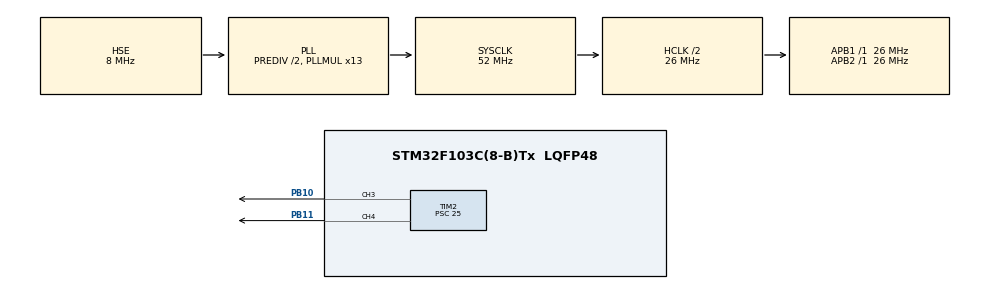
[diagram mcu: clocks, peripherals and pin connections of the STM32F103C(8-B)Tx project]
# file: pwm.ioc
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Mcu.Family=STM32F1
Mcu.Name=STM32F103C(8-B)Tx
Mcu.Package=LQFP48
NVIC.PriorityGroup=NVIC_PRIORITYGROUP_4
PA13.Mode=Serial_Wire
PA13.Signal=SYS_JTMS-SWDIO
PA14.Mode=Serial_Wire
PA14.Signal=SYS_JTCK-SWCLK
PB10.Signal=S_TIM2_CH3
PB11.Signal=S_TIM2_CH4
PD0-OSC_IN.Mode=HSE-External-Oscillator
PD0-OSC_IN.Signal=RCC_OSC_IN
PD1-OSC_OUT.Mode=HSE-External-Oscillator
PD1-OSC_OUT.Signal=RCC_OSC_OUT
ProjectManager.HeapSize=0x200
ProjectManager.StackSize=0x400
ProjectManager.TargetToolchain=STM32CubeIDE
RCC.AHBCLKDivider=RCC_SYSCLK_DIV2
RCC.AHBFreq_Value=26000000
RCC.APB1Freq_Value=26000000
RCC.APB1TimFreq_Value=26000000
RCC.APB2Freq_Value=26000000
RCC.APB2TimFreq_Value=26000000
RCC.HCLKFreq_Value=26000000
RCC.HSEDivPLL=RCC_HSE_PREDIV_DIV2
RCC.PLLMUL=RCC_PLL_MUL13
RCC.PLLSourceVirtual=RCC_PLLSOURCE_HSE
RCC.SYSCLKFreq_VALUE=52000000
RCC.SYSCLKSource=RCC_SYSCLKSOURCE_PLLCLK
RCC.USBFreq_Value=52000000
SH.S_TIM2_CH3.0=TIM2_CH3,PWM Generation3 CH3
SH.S_TIM2_CH4.0=TIM2_CH4,PWM Generation4 CH4
TIM2.Channel-PWM\ Generation3\ CH3=TIM_CHANNEL_3
TIM2.Channel-PWM\ Generation4\ CH4=TIM_CHANNEL_4
TIM2.Period=99
TIM2.Prescaler=25
VP_TIM2_VS_ClockSourceINT.Mode=Internal
board=custom

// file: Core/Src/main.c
/* USER CODE BEGIN Header */
/**
  ******************************************************************************
  * @file           : main.c
  * @brief          : Main program body
  ******************************************************************************
  * @attention
  *
  * Copyright (c) 2024 STMicroelectronics.
  * All rights reserved.
  *
  * This software is licensed under terms that can be found in the LICENSE file
  * in the root directory of this software component.
  * If no LICENSE file comes with this software, it is provided AS-IS.
  *
  ******************************************************************************
  */
/* USER CODE END Header */
#include "main.h"

TIM_HandleTypeDef htim2;

void SystemClock_Config(void);
static void MX_GPIO_Init(void);
static void MX_TIM2_Init(void);

/* USER CODE BEGIN 0 */
void pwm_set_red(uint8_t dc) {
	uint32_t arr;
	uint32_t ccr;

	arr  =__HAL_TIM_GET_AUTORELOAD(&htim2);
	arr += 1;

	ccr = (dc * arr) / 100;
	__HAL_TIM_SET_COMPARE(&htim2, TIM_CHANNEL_3, ccr);
}

void pwm_set_blue(uint8_t dc) {
	uint32_t arr;
	uint32_t ccr;

	arr  =__HAL_TIM_GET_AUTORELOAD(&htim2);
	arr += 1;

	ccr = dc * arr / 100;
	__HAL_TIM_SET_COMPARE(&htim2, TIM_CHANNEL_4, ccr);
}
/* USER CODE END 0 */

int main(void)
{

  /* USER CODE BEGIN 1 */
	uint32_t cntB, step;
  /* USER CODE END 1 */

  /* MCU Configuration--------------------------------------------------------*/

  /* Reset of all peripherals, Initializes the Flash interface and the Systick. */
  HAL_Init();

  /* Configure the system clock */
  SystemClock_Config();

  /* Initialize all configured peripherals */
  MX_GPIO_Init();
  MX_TIM2_Init();
  /* USER CODE BEGIN 2 */
  HAL_TIM_PWM_Start(&htim2, TIM_CHANNEL_3);
  HAL_TIM_PWM_Start(&htim2, TIM_CHANNEL_4);

  __HAL_TIM_SET_COMPARE(&htim2, TIM_CHANNEL_3, 50); // red
  __HAL_TIM_SET_COMPARE(&htim2, TIM_CHANNEL_4, 20); // blue
  cntB = 0;
  step = 1;
  /* USER CODE END 2 */

  /* Infinite loop */
  /* USER CODE BEGIN WHILE */
  while (1)
  {
	  cntB += step;
	  if (cntB >= 50 || cntB <= 0) step = -step;
	  pwm_set_red(cntB);
	  HAL_Delay(15);

    /* USER CODE END WHILE */

  }
}

void SystemClock_Config(void)
{
  RCC_OscInitTypeDef RCC_OscInitStruct = {0};
  RCC_ClkInitTypeDef RCC_ClkInitStruct = {0};

  /** Initializes the RCC Oscillators according to the specified parameters
  * in the RCC_OscInitTypeDef structure.
  */
  RCC_OscInitStruct.OscillatorType = RCC_OSCILLATORTYPE_HSE;
  RCC_OscInitStruct.HSEState = RCC_HSE_ON;
  RCC_OscInitStruct.HSEPredivValue = RCC_HSE_PREDIV_DIV2;
  RCC_OscInitStruct.HSIState = RCC_HSI_ON;
  RCC_OscInitStruct.PLL.PLLState = RCC_PLL_ON;
  RCC_OscInitStruct.PLL.PLLSource = RCC_PLLSOURCE_HSE;
  RCC_OscInitStruct.PLL.PLLMUL = RCC_PLL_MUL13;
  if (HAL_RCC_OscConfig(&RCC_OscInitStruct) != HAL_OK)
  {
    Error_Handler();
  }

  /** Initializes the CPU, AHB and APB buses clocks
  */
  RCC_ClkInitStruct.ClockType = RCC_CLOCKTYPE_HCLK|RCC_CLOCKTYPE_SYSCLK
                              |RCC_CLOCKTYPE_PCLK1|RCC_CLOCKTYPE_PCLK2;
  RCC_ClkInitStruct.SYSCLKSource = RCC_SYSCLKSOURCE_PLLCLK;
  RCC_ClkInitStruct.AHBCLKDivider = RCC_SYSCLK_DIV2;
  RCC_ClkInitStruct.APB1CLKDivider = RCC_HCLK_DIV1;
  RCC_ClkInitStruct.APB2CLKDivider = RCC_HCLK_DIV1;

  if (HAL_RCC_ClockConfig(&RCC_ClkInitStruct, FLASH_LATENCY_2) != HAL_OK)
  {
    Error_Handler();
  }
}

static void MX_TIM2_Init(void)
{

  TIM_ClockConfigTypeDef sClockSourceConfig = {0};
  TIM_MasterConfigTypeDef sMasterConfig = {0};
  TIM_OC_InitTypeDef sConfigOC = {0};

  htim2.Instance = TIM2;
  htim2.Init.Prescaler = 25;
  htim2.Init.CounterMode = TIM_COUNTERMODE_UP;
  htim2.Init.Period = 9999;
  htim2.Init.ClockDivision = TIM_CLOCKDIVISION_DIV1;
  htim2.Init.AutoReloadPreload = TIM_AUTORELOAD_PRELOAD_DISABLE;
  if (HAL_TIM_Base_Init(&htim2) != HAL_OK)
  {
    Error_Handler();
  }
  sClockSourceConfig.ClockSource = TIM_CLOCKSOURCE_INTERNAL;
  if (HAL_TIM_ConfigClockSource(&htim2, &sClockSourceConfig) != HAL_OK)
  {
    Error_Handler();
  }
  if (HAL_TIM_PWM_Init(&htim2) != HAL_OK)
  {
    Error_Handler();
  }
  sMasterConfig.MasterOutputTrigger = TIM_TRGO_RESET;
  sMasterConfig.MasterSlaveMode = TIM_MASTERSLAVEMODE_DISABLE;
  if (HAL_TIMEx_MasterConfigSynchronization(&htim2, &sMasterConfig) != HAL_OK)
  {
    Error_Handler();
  }
  sConfigOC.OCMode = TIM_OCMODE_PWM1;
  sConfigOC.Pulse = 0;
  sConfigOC.OCPolarity = TIM_OCPOLARITY_HIGH;
  sConfigOC.OCFastMode = TIM_OCFAST_DISABLE;
  if (HAL_TIM_PWM_ConfigChannel(&htim2, &sConfigOC, TIM_CHANNEL_3) != HAL_OK)
  {
    Error_Handler();
  }
  if (HAL_TIM_PWM_ConfigChannel(&htim2, &sConfigOC, TIM_CHANNEL_4) != HAL_OK)
  {
    Error_Handler();
  }
  HAL_TIM_MspPostInit(&htim2);

}

static void MX_GPIO_Init(void)
{

  /* GPIO Ports Clock Enable */
  __HAL_RCC_GPIOD_CLK_ENABLE();
  __HAL_RCC_GPIOB_CLK_ENABLE();
  __HAL_RCC_GPIOA_CLK_ENABLE();

}

void Error_Handler(void)
{
  __disable_irq();
  while (1)
  {
  }
}
